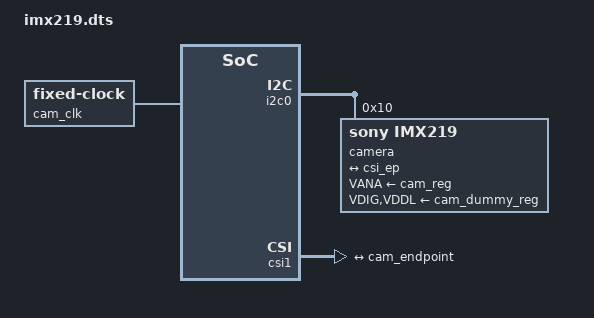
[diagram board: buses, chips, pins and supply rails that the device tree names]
// SPDX-License-Identifier: GPL-2.0
// Camera Module v2 (Sony IMX219), on the wiring the board's device tree
// describes (rpi-camera.dtsi). The firmware applies this overlay when it
// finds the camera (camera_auto_detect in config.txt). The module has its
// own 24 MHz oscillator, and is mounted upside down.
/dts-v1/;
/plugin/;

&{/} {
	cam_clk: camera-clock {
		compatible = "fixed-clock";
		#clock-cells = <0>;
		clock-frequency = <24000000>;
	};
};

&i2c0 {
	#address-cells = <1>;
	#size-cells = <0>;

	camera@10 {
		compatible = "sony,imx219";
		reg = <0x10>;
		clocks = <&cam_clk>;
		VANA-supply = <&cam_reg>;
		VDIG-supply = <&cam_dummy_reg>;
		VDDL-supply = <&cam_dummy_reg>;
		rotation = <180>;
		orientation = <2>; // external

		port {
			cam_endpoint: endpoint {
				remote-endpoint = <&csi_ep>;
				clock-lanes = <0>;
				data-lanes = <1 2>;
				clock-noncontinuous;
				link-frequencies = /bits/ 64 <456000000>;
			};
		};
	};
};

&csi1 {
	status = "okay";

	port {
		csi_ep: endpoint {
			remote-endpoint = <&cam_endpoint>;
			clock-lanes = <0>;
			data-lanes = <1 2>;
			clock-noncontinuous;
		};
	};
};
